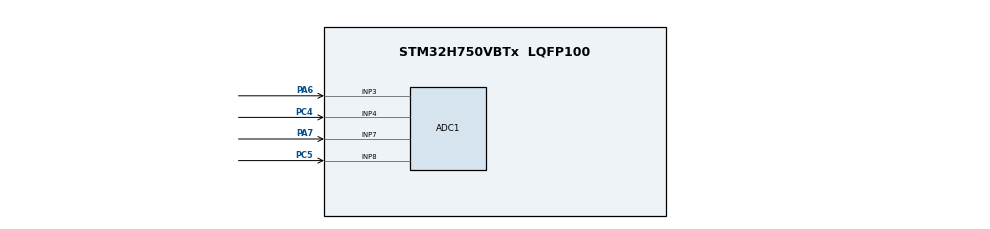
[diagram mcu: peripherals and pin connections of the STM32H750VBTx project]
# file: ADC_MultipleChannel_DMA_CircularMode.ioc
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ADC1.Channel-0\#ChannelRegularConversion=ADC_CHANNEL_3
ADC1.Channel-1\#ChannelRegularConversion=ADC_CHANNEL_4
ADC1.Channel-2\#ChannelRegularConversion=ADC_CHANNEL_7
ADC1.Channel-3\#ChannelRegularConversion=ADC_CHANNEL_8
ADC1.ClockPrescaler=ADC_CLOCK_ASYNC_DIV10
ADC1.ContinuousConvMode=ENABLE
ADC1.ConversionDataManagement=ADC_CONVERSIONDATA_DMA_CIRCULAR
ADC1.NbrOfConversion=4
ADC1.NbrOfConversionFlag=1
ADC1.OffsetNumber-0\#ChannelRegularConversion=ADC_OFFSET_NONE
ADC1.OffsetNumber-1\#ChannelRegularConversion=ADC_OFFSET_NONE
ADC1.OffsetNumber-2\#ChannelRegularConversion=ADC_OFFSET_NONE
ADC1.OffsetNumber-3\#ChannelRegularConversion=ADC_OFFSET_NONE
ADC1.OffsetSignedSaturation-0\#ChannelRegularConversion=DISABLE
ADC1.OffsetSignedSaturation-1\#ChannelRegularConversion=DISABLE
ADC1.OffsetSignedSaturation-2\#ChannelRegularConversion=DISABLE
ADC1.OffsetSignedSaturation-3\#ChannelRegularConversion=DISABLE
ADC1.Rank-0\#ChannelRegularConversion=1
ADC1.Rank-1\#ChannelRegularConversion=2
ADC1.Rank-2\#ChannelRegularConversion=3
ADC1.Rank-3\#ChannelRegularConversion=4
ADC1.SamplingTime-0\#ChannelRegularConversion=ADC_SAMPLETIME_810CYCLES_5
ADC1.SamplingTime-1\#ChannelRegularConversion=ADC_SAMPLETIME_387CYCLES_5
ADC1.SamplingTime-2\#ChannelRegularConversion=ADC_SAMPLETIME_810CYCLES_5
ADC1.SamplingTime-3\#ChannelRegularConversion=ADC_SAMPLETIME_387CYCLES_5
ADC1.master=1
CORTEX_M7.default_mode_Activation=1
Dma.ADC1.0.Direction=DMA_PERIPH_TO_MEMORY
Dma.ADC1.0.EventEnable=DISABLE
Dma.ADC1.0.FIFOMode=DMA_FIFOMODE_DISABLE
Dma.ADC1.0.Instance=DMA1_Stream0
Dma.ADC1.0.MemDataAlignment=DMA_MDATAALIGN_HALFWORD
Dma.ADC1.0.MemInc=DMA_MINC_ENABLE
Dma.ADC1.0.Mode=DMA_CIRCULAR
Dma.ADC1.0.PeriphDataAlignment=DMA_PDATAALIGN_HALFWORD
Dma.ADC1.0.PeriphInc=DMA_PINC_DISABLE
Dma.ADC1.0.Polarity=HAL_DMAMUX_REQ_GEN_RISING
Dma.ADC1.0.Priority=DMA_PRIORITY_LOW
Dma.ADC1.0.RequestNumber=1
Dma.ADC1.0.SignalID=NONE
Dma.ADC1.0.SyncEnable=DISABLE
Dma.ADC1.0.SyncPolarity=HAL_DMAMUX_SYNC_NO_EVENT
Dma.ADC1.0.SyncRequestNumber=1
Dma.ADC1.0.SyncSignalID=NONE
Dma.Request0=ADC1
Mcu.Family=STM32H7
Mcu.Name=STM32H750VBTx
Mcu.Package=LQFP100
NVIC.DMA1_Stream0_IRQn=true\:0\:0\:false\:false\:true\:false\:true\:true
NVIC.PriorityGroup=NVIC_PRIORITYGROUP_4
PA6.Signal=ADCx_INP3
PA7.Signal=ADCx_INP7
PC4.Signal=ADCx_INP4
PC5.Signal=ADCx_INP8
PH0-OSC_IN\ (PH0).Mode=HSE-External-Oscillator
PH0-OSC_IN\ (PH0).Signal=RCC_OSC_IN
PH1-OSC_OUT\ (PH1).Mode=HSE-External-Oscillator
PH1-OSC_OUT\ (PH1).Signal=RCC_OSC_OUT
ProjectManager.HeapSize=0x200
ProjectManager.StackSize=0x400
ProjectManager.TargetToolchain=STM32CubeIDE
RCC.ADCFreq_Value=75000000
RCC.APB1Freq_Value=120000000
RCC.APB2Freq_Value=120000000
RCC.APB3Freq_Value=120000000
RCC.APB4Freq_Value=120000000
RCC.CortexFreq_Value=480000000
RCC.D1PPRE=RCC_APB3_DIV2
RCC.D2PPRE1=RCC_APB1_DIV2
RCC.D2PPRE2=RCC_APB2_DIV2
RCC.D3PPRE=RCC_APB4_DIV2
RCC.DIVM1=5
RCC.DIVM2=25
RCC.DIVN1=192
RCC.DIVN2=150
RCC.HCLKFreq_Value=240000000
RCC.HPRE=RCC_HCLK_DIV2
RCC.PLLFRACN=0
RCC.PLLSourceVirtual=RCC_PLLSOURCE_HSE
RCC.SYSCLKFreq_VALUE=480000000
RCC.SYSCLKSource=RCC_SYSCLKSOURCE_PLLCLK
RCC.USBFreq_Value=480000000
SH.ADCx_INP3.0=ADC1_INP3,IN3-Single-Ended
SH.ADCx_INP4.0=ADC1_INP4,IN4-Single-Ended
SH.ADCx_INP7.0=ADC1_INP7,IN7-Single-Ended
SH.ADCx_INP8.0=ADC1_INP8,IN8-Single-Ended
VP_MEMORYMAP_VS_MEMORYMAP.Mode=CurAppReg
board=custom

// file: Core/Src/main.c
/* USER CODE BEGIN Header */
/**
  ******************************************************************************
  * @file           : main.c
  * @brief          : Main program body
  ******************************************************************************
  * @attention
  *
  * Copyright (c) 2025 STMicroelectronics.
  * All rights reserved.
  *
  * This software is licensed under terms that can be found in the LICENSE file
  * in the root directory of this software component.
  * If no LICENSE file comes with this software, it is provided AS-IS.
  *
  ******************************************************************************
  */
/* USER CODE END Header */
#include "main.h"

/* USER CODE BEGIN Includes */
#include <stdbool.h>
/* USER CODE END Includes */

ADC_HandleTypeDef hadc1;
DMA_HandleTypeDef hdma_adc1;

void SystemClock_Config(void);
static void MPU_Config(void);
static void MX_GPIO_Init(void);
static void MX_DMA_Init(void);
static void MX_ADC1_Init(void);

/* USER CODE BEGIN 0 */

uint16_t ADC_VAL[4];
bool isADCFinished = false;
int count = 0;

void HAL_ADC_ConvCpltCallback(ADC_HandleTypeDef *hadc)
{
	isADCFinished = true;
}

/* USER CODE END 0 */

int main(void)
{

  /* MPU Configuration--------------------------------------------------------*/
  MPU_Config();

  /* MCU Configuration--------------------------------------------------------*/

  /* Reset of all peripherals, Initializes the Flash interface and the Systick. */
  HAL_Init();

  /* Configure the system clock */
  SystemClock_Config();

  /* Initialize all configured peripherals */
  MX_GPIO_Init();
  MX_DMA_Init();
  MX_ADC1_Init();
  /* USER CODE BEGIN 2 */

  HAL_ADC_Start_DMA(&hadc1, (uint32_t *)ADC_VAL, 4); //In Circular mode we need to start ADC only once

  /* USER CODE END 2 */

  /* Infinite loop */
  /* USER CODE BEGIN WHILE */
  while (1)
  {
	  ++count;
	  HAL_Delay(500);
    /* USER CODE END WHILE */

  }
}

void SystemClock_Config(void)
{
  RCC_OscInitTypeDef RCC_OscInitStruct = {0};
  RCC_ClkInitTypeDef RCC_ClkInitStruct = {0};

  /** Supply configuration update enable
  */
  HAL_PWREx_ConfigSupply(PWR_LDO_SUPPLY);

  /** Configure the main internal regulator output voltage
  */
  __HAL_PWR_VOLTAGESCALING_CONFIG(PWR_REGULATOR_VOLTAGE_SCALE0);

  while(!__HAL_PWR_GET_FLAG(PWR_FLAG_VOSRDY)) {}

  /** Initializes the RCC Oscillators according to the specified parameters
  * in the RCC_OscInitTypeDef structure.
  */
  RCC_OscInitStruct.OscillatorType = RCC_OSCILLATORTYPE_HSE;
  RCC_OscInitStruct.HSEState = RCC_HSE_ON;
  RCC_OscInitStruct.PLL.PLLState = RCC_PLL_ON;
  RCC_OscInitStruct.PLL.PLLSource = RCC_PLLSOURCE_HSE;
  RCC_OscInitStruct.PLL.PLLM = 5;
  RCC_OscInitStruct.PLL.PLLN = 192;
  RCC_OscInitStruct.PLL.PLLP = 2;
  RCC_OscInitStruct.PLL.PLLQ = 2;
  RCC_OscInitStruct.PLL.PLLR = 2;
  RCC_OscInitStruct.PLL.PLLRGE = RCC_PLL1VCIRANGE_2;
  RCC_OscInitStruct.PLL.PLLVCOSEL = RCC_PLL1VCOWIDE;
  RCC_OscInitStruct.PLL.PLLFRACN = 0;
  if (HAL_RCC_OscConfig(&RCC_OscInitStruct) != HAL_OK)
  {
    Error_Handler();
  }

  /** Initializes the CPU, AHB and APB buses clocks
  */
  RCC_ClkInitStruct.ClockType = RCC_CLOCKTYPE_HCLK|RCC_CLOCKTYPE_SYSCLK
                              |RCC_CLOCKTYPE_PCLK1|RCC_CLOCKTYPE_PCLK2
                              |RCC_CLOCKTYPE_D3PCLK1|RCC_CLOCKTYPE_D1PCLK1;
  RCC_ClkInitStruct.SYSCLKSource = RCC_SYSCLKSOURCE_PLLCLK;
  RCC_ClkInitStruct.SYSCLKDivider = RCC_SYSCLK_DIV1;
  RCC_ClkInitStruct.AHBCLKDivider = RCC_HCLK_DIV2;
  RCC_ClkInitStruct.APB3CLKDivider = RCC_APB3_DIV2;
  RCC_ClkInitStruct.APB1CLKDivider = RCC_APB1_DIV2;
  RCC_ClkInitStruct.APB2CLKDivider = RCC_APB2_DIV2;
  RCC_ClkInitStruct.APB4CLKDivider = RCC_APB4_DIV2;

  if (HAL_RCC_ClockConfig(&RCC_ClkInitStruct, FLASH_LATENCY_4) != HAL_OK)
  {
    Error_Handler();
  }
}

static void MX_ADC1_Init(void)
{

  ADC_MultiModeTypeDef multimode = {0};
  ADC_ChannelConfTypeDef sConfig = {0};

  /** Common config
  */
  hadc1.Instance = ADC1;
  hadc1.Init.ClockPrescaler = ADC_CLOCK_ASYNC_DIV10;
  hadc1.Init.Resolution = ADC_RESOLUTION_16B;
  hadc1.Init.ScanConvMode = ADC_SCAN_ENABLE;
  hadc1.Init.EOCSelection = ADC_EOC_SINGLE_CONV;
  hadc1.Init.LowPowerAutoWait = DISABLE;
  hadc1.Init.ContinuousConvMode = ENABLE;
  hadc1.Init.NbrOfConversion = 4;
  hadc1.Init.DiscontinuousConvMode = DISABLE;
  hadc1.Init.ExternalTrigConv = ADC_SOFTWARE_START;
  hadc1.Init.ExternalTrigConvEdge = ADC_EXTERNALTRIGCONVEDGE_NONE;
  hadc1.Init.ConversionDataManagement = ADC_CONVERSIONDATA_DMA_CIRCULAR;
  hadc1.Init.Overrun = ADC_OVR_DATA_PRESERVED;
  hadc1.Init.LeftBitShift = ADC_LEFTBITSHIFT_NONE;
  hadc1.Init.OversamplingMode = DISABLE;
  hadc1.Init.Oversampling.Ratio = 1;
  if (HAL_ADC_Init(&hadc1) != HAL_OK)
  {
    Error_Handler();
  }

  /** Configure the ADC multi-mode
  */
  multimode.Mode = ADC_MODE_INDEPENDENT;
  if (HAL_ADCEx_MultiModeConfigChannel(&hadc1, &multimode) != HAL_OK)
  {
    Error_Handler();
  }

  /** Configure Regular Channel
  */
  sConfig.Channel = ADC_CHANNEL_3;
  sConfig.Rank = ADC_REGULAR_RANK_1;
  sConfig.SamplingTime = ADC_SAMPLETIME_810CYCLES_5;
  sConfig.SingleDiff = ADC_SINGLE_ENDED;
  sConfig.OffsetNumber = ADC_OFFSET_NONE;
  sConfig.Offset = 0;
  sConfig.OffsetSignedSaturation = DISABLE;
  if (HAL_ADC_ConfigChannel(&hadc1, &sConfig) != HAL_OK)
  {
    Error_Handler();
  }

  /** Configure Regular Channel
  */
  sConfig.Channel = ADC_CHANNEL_4;
  sConfig.Rank = ADC_REGULAR_RANK_2;
  sConfig.SamplingTime = ADC_SAMPLETIME_387CYCLES_5;
  if (HAL_ADC_ConfigChannel(&hadc1, &sConfig) != HAL_OK)
  {
    Error_Handler();
  }

  /** Configure Regular Channel
  */
  sConfig.Channel = ADC_CHANNEL_7;
  sConfig.Rank = ADC_REGULAR_RANK_3;
  sConfig.SamplingTime = ADC_SAMPLETIME_810CYCLES_5;
  if (HAL_ADC_ConfigChannel(&hadc1, &sConfig) != HAL_OK)
  {
    Error_Handler();
  }

  /** Configure Regular Channel
  */
  sConfig.Channel = ADC_CHANNEL_8;
  sConfig.Rank = ADC_REGULAR_RANK_4;
  sConfig.SamplingTime = ADC_SAMPLETIME_387CYCLES_5;
  if (HAL_ADC_ConfigChannel(&hadc1, &sConfig) != HAL_OK)
  {
    Error_Handler();
  }

}

static void MX_DMA_Init(void)
{

  /* DMA controller clock enable */
  __HAL_RCC_DMA1_CLK_ENABLE();

  /* DMA interrupt init */
  /* DMA1_Stream0_IRQn interrupt configuration */
  HAL_NVIC_SetPriority(DMA1_Stream0_IRQn, 0, 0);
  HAL_NVIC_EnableIRQ(DMA1_Stream0_IRQn);

}

static void MX_GPIO_Init(void)
{

  /* GPIO Ports Clock Enable */
  __HAL_RCC_GPIOH_CLK_ENABLE();
  __HAL_RCC_GPIOA_CLK_ENABLE();
  __HAL_RCC_GPIOC_CLK_ENABLE();

}

 /* MPU Configuration */

void MPU_Config(void)
{
  MPU_Region_InitTypeDef MPU_InitStruct = {0};

  /* Disables the MPU */
  HAL_MPU_Disable();

  /** Initializes and configures the Region and the memory to be protected
  */
  MPU_InitStruct.Enable = MPU_REGION_ENABLE;
  MPU_InitStruct.Number = MPU_REGION_NUMBER0;
  MPU_InitStruct.BaseAddress = 0x0;
  MPU_InitStruct.Size = MPU_REGION_SIZE_4GB;
  MPU_InitStruct.SubRegionDisable = 0x87;
  MPU_InitStruct.TypeExtField = MPU_TEX_LEVEL0;
  MPU_InitStruct.AccessPermission = MPU_REGION_NO_ACCESS;
  MPU_InitStruct.DisableExec = MPU_INSTRUCTION_ACCESS_DISABLE;
  MPU_InitStruct.IsShareable = MPU_ACCESS_SHAREABLE;
  MPU_InitStruct.IsCacheable = MPU_ACCESS_NOT_CACHEABLE;
  MPU_InitStruct.IsBufferable = MPU_ACCESS_NOT_BUFFERABLE;

  HAL_MPU_ConfigRegion(&MPU_InitStruct);
  /* Enables the MPU */
  HAL_MPU_Enable(MPU_PRIVILEGED_DEFAULT);

}

void Error_Handler(void)
{
  __disable_irq();
  while (1)
  {
  }
}
